# f1c100s register map
Vendor: Allwinner; File version: 1.0
The Allwinner F1C100s is a small SoC with an ARM926EJ-S CPU core and 32MB of embedded DDR SDRAM.
Registers are 32-bit, read-write, reset 0x0 unless marked. A register's access mark holds for its fields unless they carry their own. Offsets are from the block's base; lines under a group give offsets from that group; [hi:lo] are bit positions; {n}, {i} and the like mark numbered series; 'fields as' and 'values as' point back to an identical list; <NAME> marks a mode.

## Memory map
0x01C02000 DMA size 0x400 — DMA Controller - 4 Normal DMA (NDMA) channels and 4 Dedicated DMA (DDMA) channels
0x01C20000 CCU size 0x400 — Clock Control Unit - PLLs, Bus Clocks, Gating and Reset
0x01C20400 INTC size 0x70 — Interrupt Controller - Handles up to 64 interrupt sources with 4-level priority, fast forcing, and NMI support
0x01C20800 PIO size 0x300 — Port Controller (GPIO)
0x01C20C00 TIMER size 0x100 — Timer, Watchdog and AVS Counter
{0x1C25000+0x400*n} UART{n} (n=0..2) size 0x400 — Universal asynchronous receiver/transmitter

## UART{n} — Universal asynchronous receiver/transmitter
Base 0x01C25000; array of 3, step 0x400
0x00 RBR ro (alternate view of THR) — Receive Buffer Register
  [7:0] DATA — Data byte received
0x00 THR wo (alternate view of RBR) — Transmit Holding Register
  [7:0] DATA — Data byte to transmit
0x00 DLL (alternate view of RBR) — Divisor Latch Low Register (DLAB=1)
  [7:0] DLL — Lower 8 bits of baud rate divisor
0x04 DLH (alternate view of IER) — Divisor Latch High Register (DLAB=1)
  [7:0] DLH — Upper 8 bits of baud rate divisor
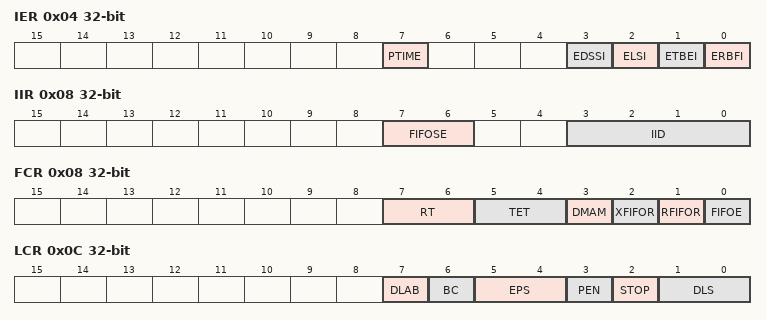
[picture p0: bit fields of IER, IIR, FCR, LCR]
0x04 IER (alternate view of DLH) — Interrupt Enable Register
  [7] PTIME — Programmable THRE Interrupt Mode Enable
  [3] EDSSI — Enable Modem Status Interrupt
  [2] ELSI — Enable Receiver Line Status Interrupt
  [1] ETBEI — Enable Transmit Holding Register Empty Interrupt
  [0] ERBFI — Enable Received Data Available Interrupt
0x08 IIR ro (alternate view of FCR) — Interrupt Identity Register
  [7:6] FIFOSE — FIFOs Enabled
  [3:0] IID — Interrupt ID
0x08 FCR wo (alternate view of IIR) — FIFO Control Register
  [7:6] RT — Receiver Trigger Level
  [5:4] TET — TX Empty Trigger Level
  [3] DMAM — DMA Mode
  [2] XFIFOR — TX FIFO Reset
  [1] RFIFOR — RX FIFO Reset
  [0] FIFOE — FIFO Enable
0x0C LCR — Line Control Register
  [7] DLAB — Divisor Latch Access Bit
  [6] BC — Break Control
  [5:4] EPS — Even Parity Select
  [3] PEN — Parity Enable
  [2] STOP — Number of Stop Bits
  [1:0] DLS — Data Length Select
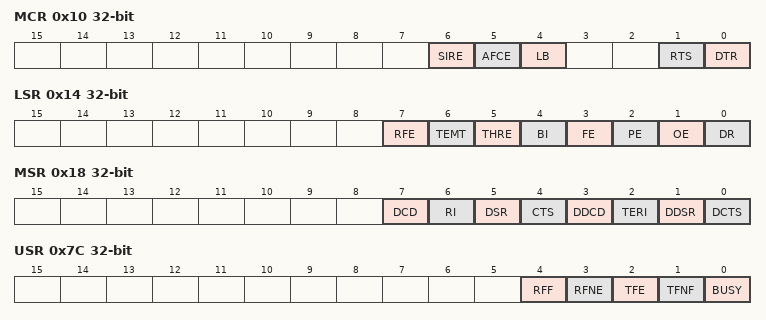
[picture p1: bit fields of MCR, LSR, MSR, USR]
0x10 MCR — Modem Control Register
  [6] SIRE — SIR Mode Enable
  [5] AFCE — Auto Flow Control Enable
  [4] LB — Loop Back Mode
  [1] RTS — Request to Send
  [0] DTR — Data Terminal Ready
0x14 LSR ro — Line Status Register
  [7] RFE — RX FIFO Error
  [6] TEMT — Transmitter Empty
  [5] THRE — TX Holding Register Empty
  [4] BI — Break Interrupt
  [3] FE — Framing Error
  [2] PE — Parity Error
  [1] OE — Overrun Error
  [0] DR — Data Ready
0x18 MSR ro — Modem Status Register
  [7] DCD — Data Carrier Detect
  [6] RI — Ring Indicator
  [5] DSR — Data Set Ready
  [4] CTS — Clear to Send
  [3] DDCD — Delta Data Carrier Detect
  [2] TERI — Trailing Edge Ring Indicator
  [1] DDSR — Delta Data Set Ready
  [0] DCTS — Delta Clear to Send
0x1C SCR — Scratch Register
  [7:0] SCR — Scratch data
0x7C USR ro — UART Status Register
  [4] RFF — RX FIFO Full
  [3] RFNE — RX FIFO Not Empty
  [2] TFE — TX FIFO Empty
  [1] TFNF — TX FIFO Not Full
  [0] BUSY — UART Busy
0x80 TFL ro — Transmit FIFO Level
  [6:0] TFL — TX FIFO data count
0x84 RFL ro — Receive FIFO Level
  [6:0] RFL — RX FIFO data count
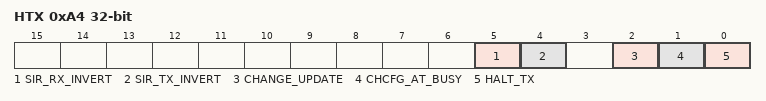
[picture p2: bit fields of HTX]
0xA4 HTX — Halt TX Register
  [5] SIR_RX_INVERT — SIR RX Pulse Polarity Invert
  [4] SIR_TX_INVERT — SIR TX Pulse Polarity Invert
  [2] CHANGE_UPDATE — Configuration Update Trigger
  [1] CHCFG_AT_BUSY — Change Config While Busy
  [0] HALT_TX
0xB0 DBG_DLL — Debug Divisor Latch Low
  [7:0] DBG_DLL — Debug DLL value
0xB4 DBG_DLH — Debug Divisor Latch High
  [7:0] DBG_DLH — Debug DLH value

## Licence text in the file
THIS SOFTWARE IS PROVIDED ON AN "AS IS" BASIS, WITHOUT WARRANTIES OF ANY KIND, EITHER EXPRESS OR IMPLIED, INCLUDING BUT NOT LIMITED TO NON-INFRINGEMENT, MERCHANTABILITY OR FIT FOR A PARTICULAR PURPOSE. See the Mulan PSL v2 for more details.
